AUTOSAR XML (schema 4-2-2)
package /IoHwAb_DIO_Test
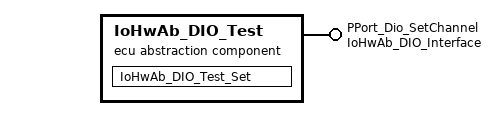
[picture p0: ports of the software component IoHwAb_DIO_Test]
  ecu abstraction sw component type IoHwAb_DIO_Test
    provide port PPort_Dio_SetChannel: provided-interface=IoHwAb_DIO_Interface
    behavior IB_IoHwAb_DIO_Test
      operation invoked event OperationInvokedEvent_0: start-on-event=IoHwAb_DIO_Test_Set, operation=PPort_Dio_SetChannel.Dio_Write
      runnable IoHwAb_DIO_Test_Set: symbol=IoHwAb_DIO_Test_Set_func
